# 3065HRPICZ register map
File version: 1.0
Registers are 32-bit, access per field, reset 0x0 unless marked. A register's access mark holds for its fields unless they carry their own. Offsets are from the block's base; [hi:lo] are bit positions; {n}, {i} and the like mark numbered series.

## DMA — DMA peripheral interface
Base 0x1C000000
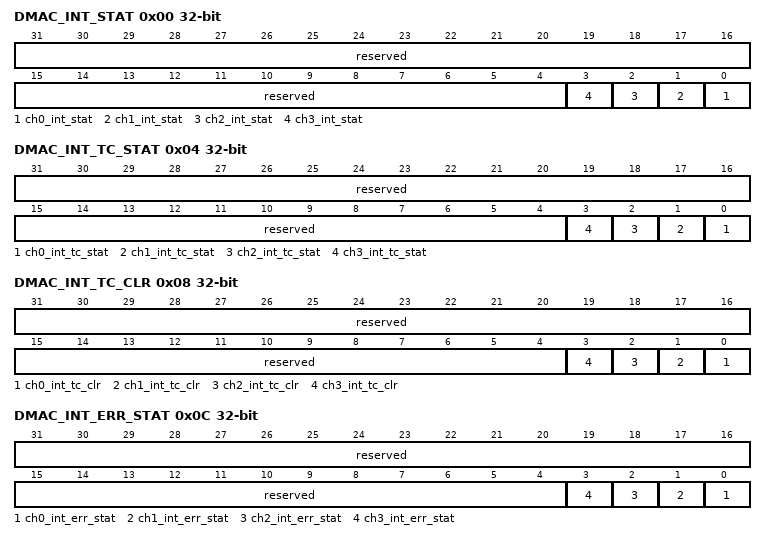
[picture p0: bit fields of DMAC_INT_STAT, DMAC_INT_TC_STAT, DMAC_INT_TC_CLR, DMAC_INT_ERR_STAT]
0x00 DMAC_INT_STAT ro — 中断状态寄存器
  [31:4] reserved — 保留
  [n] ch{n}_int_stat (n=0..3) — 通道{n}经屏蔽后的中断状态。 0：未产生中断； 1：已产生中断（传输错误或传输完成）。
0x04 DMAC_INT_TC_STAT ro — 传输完成中断状态寄存器
  [31:4] reserved — 保留
  [n] ch{n}_int_tc_stat (n=0..3) — 通道{n}经屏蔽后的传输完成中断状态。 0：未产生中断； 1：已产生中断。
0x08 DMAC_INT_TC_CLR — 传输完成中断清除寄存器
  [31:4] reserved ro — 保留
  [n] ch{n}_int_tc_clr wo (n=0..3) — 清除通道{n}传输完成中断。 0：不清除； 1：清除。
0x0C DMAC_INT_ERR_STAT ro — 错误中断状态寄存器
  [31:4] reserved — 保留
  [n] ch{n}_int_err_stat (n=0..3) — 通道{n}经屏蔽后的错误中断状态。 0：未产生中断； 1：已产生中断。
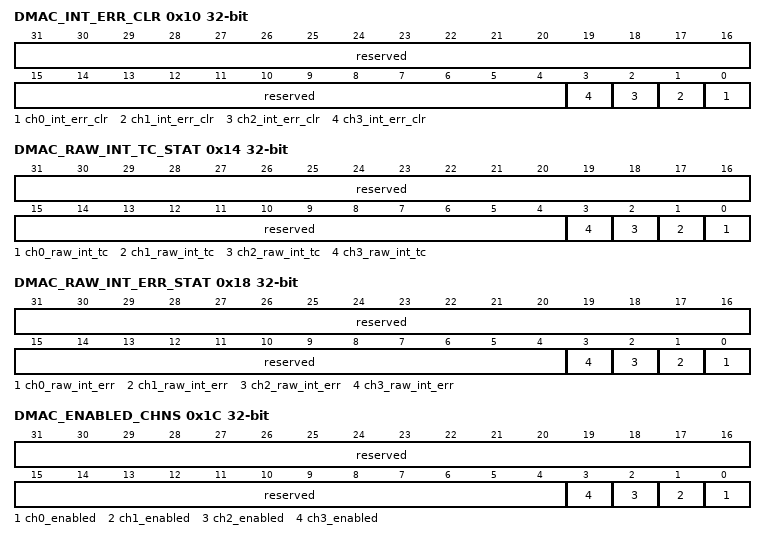
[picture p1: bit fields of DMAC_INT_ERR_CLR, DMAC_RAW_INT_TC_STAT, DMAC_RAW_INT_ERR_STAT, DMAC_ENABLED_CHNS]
0x10 DMAC_INT_ERR_CLR — 错误中断清除寄存器
  [31:4] reserved ro — 保留
  [n] ch{n}_int_err_clr wo (n=0..3) — 清除通道{n}错误中断。 0：不清除； 1：清除。
0x14 DMAC_RAW_INT_TC_STAT ro — 原始传输完成中断状态寄存器
  [31:4] reserved — 保留
  [n] ch{n}_raw_int_tc (n=0..3) — 通道{n}原始传输完成中断状态。 0：未产生传输完成中断； 1：产生传输完成中断。
0x18 DMAC_RAW_INT_ERR_STAT ro — 原始错误中断寄存器
  [31:4] reserved — 保留
  [n] ch{n}_raw_int_err (n=0..3) — 通道{n}原始错误中断状态。 0：未产生错误中断； 1：产生错误中断。
0x1C DMAC_ENABLED_CHNS ro — 通道使能状态寄存器
  [31:4] reserved — 保留
  [n] ch{n}_enabled (n=0..3) — 通道{n}使能状态。 0：禁止； 1：使能。
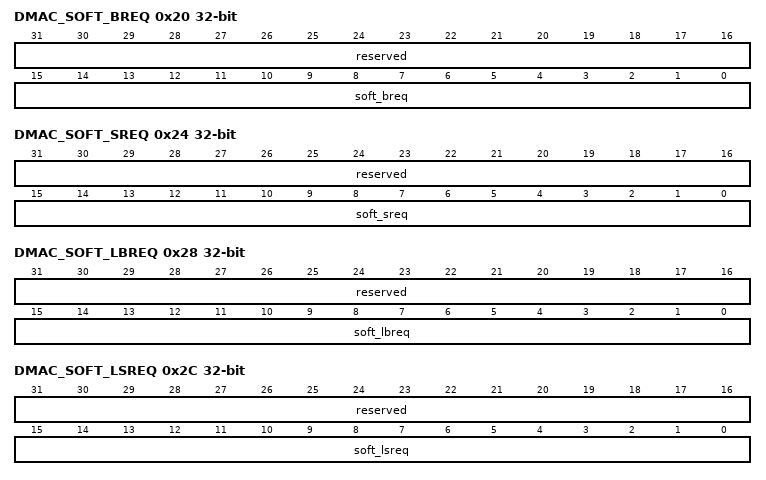
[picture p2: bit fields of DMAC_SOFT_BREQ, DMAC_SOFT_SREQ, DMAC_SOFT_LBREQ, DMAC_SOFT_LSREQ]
0x20 DMAC_SOFT_BREQ — 软件 BURST 传输请求寄存器
  [31:16] reserved ro — 保留
  [15:0] soft_breq rw — 用于软件控制产生 DMA BURST 传输请求，每比特对应 请求请参见 DMAC 的硬件请求线。 当写该寄存器时： 0：无影响； 1：产生 DMA BURST 传输请求，当传输结束时该寄存 器中的相应位被清零。 当读该寄存器时： 0：与请求线 DMACBREQ[15:0]对应的外设未发出 DMA BURST 请求； 1：与请求线 DMACBREQ[15:0]对应的外设正在请求 DMA BURST 传输。
0x24 DMAC_SOFT_SREQ — 软件SINGLE传输请求寄存器
  [31:16] reserved ro — 保留
  [15:0] soft_sreq rw — 用于软件控制产生 DMA SINGLE 传输请求，每比特对应 请求请参见 DMAC 的硬件请求线。 当写该寄存器时： 0：无影响； 1：产生 DMA SINGLE 传输请求，当传输结束时该寄存 器中的相应位被清零。 当读该寄存器时： 0：与请求线 DMACSREQ[15:0]对应的外设未发出 DMA SINGLE 请求； 1：与请求线 DMACSREQ[15:0]对应的外设正在请求 DMA SINGLE 传输。
0x28 DMAC_SOFT_LBREQ — 软件最后一个BURST请求寄存器
  [31:16] reserved ro — 保留
  [15:0] soft_lbreq rw — 由软件发起 last burst 请求。 0：无影响； 1：产生 DMA last burst 传输请求，当传输结束时该寄 存器中的相应位被清零。
0x2C DMAC_SOFT_LSREQ — 软件最后一个SINGLE请求寄存器
  [31:16] reserved ro — 保留
  [15:0] soft_lsreq rw — 由软件发起 last single 传输请求。 0：无影响； 1：产生一个 DMA last single 传输请求，当传输结束时 该寄存器中的相应位被清零。
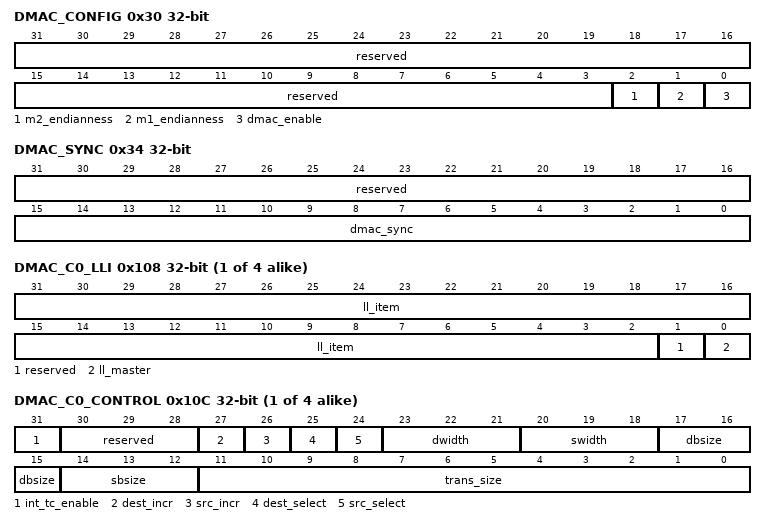
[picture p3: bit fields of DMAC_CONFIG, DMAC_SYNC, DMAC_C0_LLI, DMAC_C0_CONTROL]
0x30 DMAC_CONFIG — DMAC配置寄存器
  [31:3] reserved ro — 保留
  [2] m2_endianness rw — Master 2 字节顺序配置。 0：小端格式； 1：大端格式。
  [1] m1_endianness rw — Master 1 字节顺序配置。 0：小端格式； 1：大端格式。
  [0] dmac_enable rw — DMA 控制器使能。 0：禁止 DMA 控制器； 1：使能 DMA 控制器。
0x34 DMAC_SYNC — 请求线同步使能寄存器
  [31:16] reserved ro — 保留
  [15:0] dmac_sync rw — 控制是否需要对请求线进行同步，每比特对应请求请 参见 DMAC 的硬件请求线。 0：使能对应外设的 DMA 请求信号同步逻辑； 1：禁止对应外设的 DMA 请求信号同步逻辑。
{0x100+0x20*i} DMAC_C{i}_SRC_ADDR rw (i=0..3) — 通道{i}源地址寄存器
  [31:0] src_addr — DMA 源地址
{0x104+0x20*i} DMAC_C{i}_DEST_ADDR rw (i=0..3) — 通道{i}目的地址寄存器
  [31:0] dest_addr — DMA目的地址
{0x108+0x20*i} DMAC_C{i}_LLI rw (i=0..3) — 通道{i}链表信息寄存器
  [31:2] ll_item — 下一个链表节点地址的[31:2]位，地址位[1:0]为 0。要求链 表地址 4Byte 对齐。
  [1] reserved — 保留，写入时必须写 0，读出时应屏蔽该位。
  [0] ll_master — 用于载入下一个链表节点的 Master。 0： Master 1； 1： Master 2。
{0x10C+0x20*i} DMAC_C{i}_CONTROL (i=0..3) — 通道{i}控制寄存器
  [31] int_tc_enable rw — 传输完成中断使能位。该位用于决定当前链表节点是否触 发传输完成中断。 0：当前链表节点不触发传输完成中断； 1：当前链表节点触发传输完成中断。
  [30:28] reserved ro — 保留
  [27] dest_incr rw — 目的地址递增。 0：目的地址不递增； 1：目的地址每传一个数就递增一次。 目的设备为外设时目的地址不递增；目的设备为存储器时 目的地址递增。
  [26] src_incr rw — 源地址递增。 0：源地址不递增； 1：源地址每传一个数就递增一次。 源设备为外设时源地址不递增；源设备为存储器时源地址 递增。
  [25] dest_select rw — 设置访问目的设备的 master。 0：使用 master1 访问； 1：使用 master2 访问。
  [24] src_select rw — 设置访问源设备的 master。 0：使用 master1 访问； 1：使用 master2 访问。
  [23:21] dwidth rw — 目的设备传输位宽。 宽于 Master 位宽的传输位宽是非法的。 目的设备和源设备的位宽可以不一样，硬件自动对数据进 行 pack 和 unpack。
  [20:18] swidth rw — 源设备传输位宽。 宽于 Master 位宽的传输位宽是非法的。 目的设备和源设备的位宽可以不一样，硬件自动对数据进 行 pack 和 unpack。
  [17:15] dbsize rw — 目的设备 burst 长度。 表示目的设备请求 1 次 burst 传输（BREQ）， DMAC 向 目的地址（固定或递增地址）写数据的个数。 若目的设备是外设， 内部有 FIFO， burst 长度不能超过其 FIFO 深度， 建议配合 FIFO 水线使用。 若目的设备是外设， 内部无 FIFO，若配置了目的地址递 增，则 burst 长度不能超过外设的地址空间。 否则，递增 的目的地址会超过该设备的地址空间，若该地址无映射， 那么可能导致无法预料的结果。 若目的设备是存储器， 若配置了目的地址递增， 则 burst 长度的配置需要考虑存储器地址边界。 目的地址+burst 长 度不能超过其存储器地址边界。 否则， 目的地址递增会访 问到超过该设备的地址空间，若该地址无映射，那么可能 导致无法预料的结果。
  [14:12] sbsize rw — 源设备 burst 长度。 表示源设备请求 1 次 burst 传输（BREQ）， DMAC 从源 地址（固定或递增地址）读数据的个数。 若源设备是外设， 内部有 FIFO， burst 长度不能超过其 FIFO 深度， 建议配合 FIFO 水线使用。 若源设备是外设， 内部无 FIFO，若配置了源地址递增，则 burst 长度不能超过外设的地址空间。 否则，递增的源地址 会超过该设备的地址空间，若该地址无映射，那么可能导 致无法预料的结果。 若源设备是存储器， 若配置了源地址递增， 则 burst 长度 的配置需要考虑存储器地址边界。 源地址+burst 长度不能 超过其存储器地址边界。 否则， 源地址递增会访问到超过 该设备的地址空间，若该地址无映射，那么可能导致无法 预料的结果。
  [11:0] trans_size rw — 通过写该寄存器可设定 DMA 传输的长度，前提是 DMAC 是流控制器。这里 transfer size 表示的源设备待传数据的 个数。 读该寄存器可得到在与目的设备相连的总线上已传出的数 据个数。 当该通道处于活动状态时，读该寄存器得不到有效信息。 这是因为当软件得到读出的寄存器值，该寄存器的值已经 随着通道传输改变了。对该寄存器的读操作一般是用在通 道被启动后然后又停止传输时。
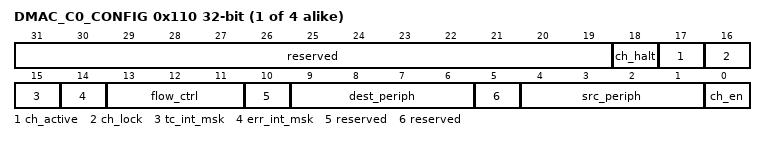
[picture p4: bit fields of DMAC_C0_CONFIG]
{0x110+0x20*i} DMAC_C{i}_CONFIG (i=0..3) — 通道{i}配置寄存器
  [31:19] reserved rw — 保留。 写入时必须写入 0，读出时应被屏蔽。
  [18] ch_halt rw — Halt 位。 0：允许 DMA 请求； 1：忽略后来的 DMA 请求，通道 FIFO 中的内容都被传 完。 该位可以和 Active 位以及通道使能位一起用于无数据丢失 地关闭一个 DMA 通道。
  [17] ch_active ro — Active 位。 0：通道 FIFO 中没有数据； 1：通道 FIFO 中有数据。 该位可以和 Halt 位以及通道使能位一起用于无数据丢失地 关闭一个 DMA 通道。
  [16] ch_lock rw — Lock 位。 0：禁止总线上 lock 传输； 1：使能总线上 lock 传输。
  [15] tc_int_msk rw — 传输完成中断屏蔽位。 0：屏蔽本通道的传输完成中断。 1：不屏蔽本通道的传输完成中断。
  [14] err_int_msk rw — 错误中断屏蔽位。 0：屏蔽本通道的错误中断。 1：不屏蔽本通道的错误中断。
  [13:11] flow_ctrl rw — 流控及传输类型字段。 该字段用于指定流控制器和传输类型。流控制器可以是 DMAC、源设备和目的设备。 传输类型可以是存储器到外设、外设到存储器、外设到外 设、存储器到存储器。
  [10] reserved rw — 保留。 写入时必须写入 0，读出时应被屏蔽。
  [9:6] dest_periph rw — 目的设备。该字段用于选择一个外设请求信号作为本通道 的 DMA 目的设备的请求信号。 如果 DMA 传输的目的设备是存储器则该字段被忽略。
  [5] reserved rw — 保留。 写入时必须写入 0，读出时应被屏蔽。
  [4:1] src_periph rw — 源设备。该字段用于选择一个外设请求信号作为本通道的 DMA 源设备的请求信号。 如果 DMA 传输的源设备是存储器则该字段被忽略。
  [0] ch_en rw — 通道使能位。读该寄存器可得知本通道当前是处于什么状 态（也可通过读寄存器 DMAC_ENABLED_CHNS 得 到） 。 0：关闭通道； 1：启动通道。 通过清零可关闭通道。将该位被清零时，当前的总线传输 会继续执行直到完成。然后通道关闭， FIFO 中剩余的数据 全部丢失；当最后一个 LLI 完成或传输中出现错误时，通 道也会被关闭，同时该位被清零；如果要关闭通道，而又 不使通道 FIFO 中的数据丢失，则 Halt 位也必须同时被置 位，使通道忽略后来的 DMA 请求。然后必须轮询 active 位，直到其值变为 0，表明通道 FIFO 中不再留有数据。此 时才能够清除 enable 位。 通过置位启动通道必须先重新初始化通道，然后才能再次 启动通道；若通过简单的置位启动通道，会引发不可预测 性的后果。 当刚通过写 DMAC_Cn_CONFIG [0]位关闭一个通道时，必 须要等到轮询到寄存器 DMAC_ENABLED_CHNS 中的相 应 bit 为 0 后，才能将 DMAC_Cn_CONFIG [0]重新置位。 这是因为通道实际的关闭并没有在将 DMAC_Cn_CONFIG [0]清零后立即生效。总线 burst 的运行时延时也必须要考 虑到。
